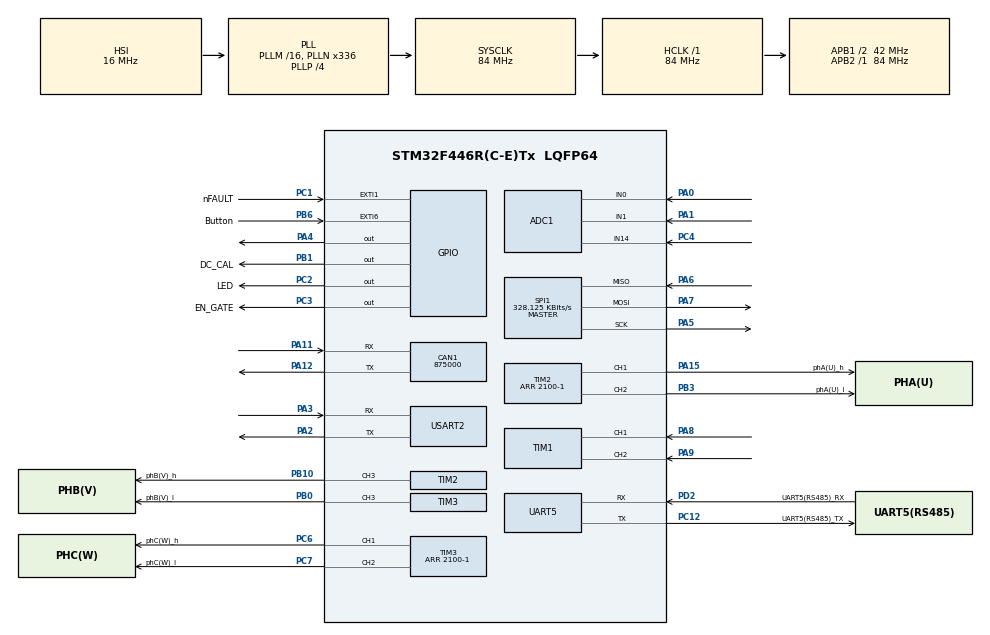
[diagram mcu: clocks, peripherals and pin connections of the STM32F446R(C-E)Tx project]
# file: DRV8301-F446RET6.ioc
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ADC1.Channel-0\#ChannelRegularConversion=ADC_CHANNEL_14
ADC1.Channel-2\#ChannelInjectedConversion=ADC_CHANNEL_0
ADC1.Channel-4\#ChannelInjectedConversion=ADC_CHANNEL_1
ADC1.ClockPrescaler=ADC_CLOCK_SYNC_PCLK_DIV4
ADC1.ContinuousConvMode=DISABLE
ADC1.ExternalTrigConv=ADC_SOFTWARE_START
ADC1.ExternalTrigInjecConv=ADC_EXTERNALTRIGINJECCONV_T2_TRGO
ADC1.InjNumberOfConversion=2
ADC1.InjectedConvMode=None
ADC1.InjectedOffset-2\#ChannelInjectedConversion=0
ADC1.InjectedOffset-4\#ChannelInjectedConversion=0
ADC1.InjectedRank-2\#ChannelInjectedConversion=1
ADC1.InjectedRank-4\#ChannelInjectedConversion=2
ADC1.NbrOfConversion=1
ADC1.NbrOfConversionFlag=1
ADC1.Rank-0\#ChannelRegularConversion=1
ADC1.SamplingTime-0\#ChannelRegularConversion=ADC_SAMPLETIME_3CYCLES
ADC1.SamplingTime-2\#ChannelInjectedConversion=ADC_SAMPLETIME_56CYCLES
ADC1.SamplingTime-4\#ChannelInjectedConversion=ADC_SAMPLETIME_56CYCLES
ADC1.ScanConvMode=ENABLE
ADC1.master=1
CAN1.BS1=CAN_BS1_1TQ
CAN1.BS2=CAN_BS2_1TQ
CAN1.CalculateBaudRate=875000
CAN1.CalculateTimeBit=1142
CAN1.CalculateTimeQuantum=380.95238095238096
Mcu.Family=STM32F4
Mcu.Name=STM32F446R(C-E)Tx
Mcu.Package=LQFP64
NVIC.ADC_IRQn=true\:0\:0\:false\:false\:true\:true\:true\:true
NVIC.EXTI1_IRQn=true\:0\:0\:false\:false\:true\:true\:true\:true
NVIC.EXTI9_5_IRQn=true\:0\:0\:false\:false\:true\:true\:true\:true
NVIC.PriorityGroup=NVIC_PRIORITYGROUP_4
NVIC.SPI1_IRQn=true\:0\:0\:false\:false\:true\:true\:true\:true
NVIC.TIM1_UP_TIM10_IRQn=true\:0\:0\:false\:false\:true\:true\:true\:true
NVIC.TIM3_IRQn=true\:0\:0\:false\:false\:true\:true\:true\:true
NVIC.TIM8_TRG_COM_TIM14_IRQn=true\:15\:0\:false\:false\:true\:false\:true\:true
NVIC.TimeBase=TIM8_TRG_COM_TIM14_IRQn
NVIC.TimeBaseIP=TIM14
NVIC.UART5_IRQn=true\:0\:0\:false\:false\:true\:true\:true\:true
NVIC.USART2_IRQn=true\:0\:0\:false\:false\:true\:true\:true\:true
PA0-WKUP.Signal=ADCx_IN0
PA1.Signal=ADCx_IN1
PA11.Mode=CAN_Activate
PA11.Signal=CAN1_RX
PA12.Mode=CAN_Activate
PA12.Signal=CAN1_TX
PA13.Mode=Serial_Wire
PA13.Signal=SYS_JTMS-SWDIO
PA14.Mode=Serial_Wire
PA14.Signal=SYS_JTCK-SWCLK
PA15.GPIO_Label=phA(U)_h
PA15.Signal=S_TIM2_CH1_ETR
PA2.Mode=Asynchronous
PA2.Signal=USART2_TX
PA3.Mode=Asynchronous
PA3.Signal=USART2_RX
PA4.GPIO_Label=SPI\uFF12\uFF3FNSS\uFF08CS\uFF09
PA4.GPIO_Speed=GPIO_SPEED_FREQ_VERY_HIGH
PA4.PinState=GPIO_PIN_SET
PA4.Signal=GPIO_Output
PA5.Mode=Full_Duplex_Master
PA5.Signal=SPI1_SCK
PA6.Mode=Full_Duplex_Master
PA6.Signal=SPI1_MISO
PA7.Mode=Full_Duplex_Master
PA7.Signal=SPI1_MOSI
PA8.Signal=S_TIM1_CH1
PA9.Signal=S_TIM1_CH2
PB0.GPIO_Label=phB(V)_l
PB0.Signal=S_TIM3_CH3
PB1.GPIO_Label=DC_CAL
PB1.PinState=GPIO_PIN_RESET
PB1.Signal=GPIO_Output
PB10.GPIO_Label=phB(V)_h
PB10.Signal=S_TIM2_CH3
PB3.GPIO_Label=phA(U)_l
PB3.Signal=S_TIM2_CH2
PB6.GPIO_Label=Button
PB6.GPIO_ModeDefaultEXTI=GPIO_MODE_IT_FALLING
PB6.Signal=GPXTI6
PC1.GPIO_Label=nFAULT
PC1.GPIO_ModeDefaultEXTI=GPIO_MODE_IT_FALLING
PC1.GPIO_PuPd=GPIO_PULLUP
PC1.Signal=GPXTI1
PC12.GPIO_Label=UART5(RS485)_TX
PC12.Mode=Asynchronous
PC12.Signal=UART5_TX
PC13.Mode=SYS_WakeUp1
PC13.Signal=SYS_WKUP1
PC14-OSC32_IN.Mode=LSE-External-Oscillator
PC14-OSC32_IN.Signal=RCC_OSC32_IN
PC15-OSC32_OUT.Mode=LSE-External-Oscillator
PC15-OSC32_OUT.Signal=RCC_OSC32_OUT
PC2.GPIO_Label=LED
PC2.Signal=GPIO_Output
PC3.GPIO_Label=EN_GATE
PC3.Signal=GPIO_Output
PC4.Signal=ADCx_IN14
PC6.GPIO_Label=phC(W)_h
PC6.Signal=S_TIM3_CH1
PC7.GPIO_Label=phC(W)_l
PC7.Signal=S_TIM3_CH2
PD2.GPIO_Label=UART5(RS485)_RX
PD2.Mode=Asynchronous
PD2.Signal=UART5_RX
PH0-OSC_IN.Mode=HSE-External-Oscillator
PH0-OSC_IN.Signal=RCC_OSC_IN
PH1-OSC_OUT.Mode=HSE-External-Oscillator
PH1-OSC_OUT.Signal=RCC_OSC_OUT
ProjectManager.HeapSize=0x200
ProjectManager.StackSize=0x400
ProjectManager.TargetToolchain=CMake
RCC.AHBFreq_Value=84000000
RCC.APB1CLKDivider=RCC_HCLK_DIV2
RCC.APB1Freq_Value=42000000
RCC.APB1TimFreq_Value=84000000
RCC.APB2Freq_Value=84000000
RCC.APB2TimFreq_Value=84000000
RCC.CortexFreq_Value=84000000
RCC.HCLKFreq_Value=84000000
RCC.PLLN=336
RCC.PLLP=RCC_PLLP_DIV4
RCC.SYSCLKFreq_VALUE=84000000
RCC.SYSCLKSource=RCC_SYSCLKSOURCE_PLLCLK
RCC.USBFreq_Value=168000000
RCC.VCOOutputFreq_Value=336000000
SH.ADCx_IN0.0=ADC1_IN0,IN0
SH.ADCx_IN1.0=ADC1_IN1,IN1
SH.ADCx_IN14.0=ADC1_IN14,IN14
SH.S_TIM1_CH1.0=TIM1_CH1,Encoder_Interface
SH.S_TIM1_CH2.0=TIM1_CH2,Encoder_Interface
SH.S_TIM2_CH1_ETR.0=TIM2_CH1,PWM Generation1 CH1
SH.S_TIM2_CH2.0=TIM2_CH2,PWM Generation2 CH2
SH.S_TIM2_CH3.0=TIM2_CH3,PWM Generation3 CH3
SH.S_TIM3_CH1.0=TIM3_CH1,PWM Generation1 CH1
SH.S_TIM3_CH2.0=TIM3_CH2,PWM Generation2 CH2
SH.S_TIM3_CH3.0=TIM3_CH3,PWM Generation3 CH3
SPI1.BaudRatePrescaler=SPI_BAUDRATEPRESCALER_256
SPI1.CalculateBaudRate=328.125 KBits/s
SPI1.DataSize=SPI_DATASIZE_16BIT
SPI1.Direction=SPI_DIRECTION_2LINES
SPI1.Mode=SPI_MODE_MASTER
SPI1.VirtualType=VM_MASTER
TIM1.EncoderMode=TIM_ENCODERMODE_TI12
TIM10.Period=1000-1
TIM10.Prescaler=8400-1
TIM2.AutoReloadPreload=TIM_AUTORELOAD_PRELOAD_ENABLE
TIM2.Channel-PWM\ Generation1\ CH1=TIM_CHANNEL_1
TIM2.Channel-PWM\ Generation2\ CH2=TIM_CHANNEL_2
TIM2.Channel-PWM\ Generation3\ CH3=TIM_CHANNEL_3
TIM2.Channel-PWM\ Generation4\ No\ Output=TIM_CHANNEL_4
TIM2.CounterMode=TIM_COUNTERMODE_CENTERALIGNED1
TIM2.OCMode_PWM-PWM\ Generation4\ No\ Output=TIM_OCMODE_PWM2
TIM2.Period=2100-1
TIM2.TIM_MasterOutputTrigger=TIM_TRGO_OC4REF
TIM3.AutoReloadPreload=TIM_AUTORELOAD_PRELOAD_ENABLE
TIM3.Channel-PWM\ Generation1\ CH1=TIM_CHANNEL_1
TIM3.Channel-PWM\ Generation2\ CH2=TIM_CHANNEL_2
TIM3.Channel-PWM\ Generation3\ CH3=TIM_CHANNEL_3
TIM3.CounterMode=TIM_COUNTERMODE_CENTERALIGNED1
TIM3.Period=2100-1
TIM3.TIM_MasterOutputTrigger=TIM_TRGO_RESET
TIM3.TIM_MasterSlaveMode=TIM_MASTERSLAVEMODE_DISABLE
UART5.VirtualMode=Asynchronous
USART2.VirtualMode=VM_ASYNC
VP_SYS_VS_tim14.Mode=TIM14
VP_TIM10_VS_ClockSourceINT.Mode=Enable_Timer
VP_TIM2_VS_ClockSourceINT.Mode=Internal
VP_TIM2_VS_no_output4.Mode=PWM Generation4 No Output
VP_TIM3_VS_ClockSourceINT.Mode=Internal
VP_TIM3_VS_ClockSourceITR.Mode=TriggerSource_ITR1
VP_TIM3_VS_ControllerModeReset.Mode=Reset Mode
board=custom

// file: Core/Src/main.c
/* USER CODE BEGIN Header */
/**
  ******************************************************************************
  * @file           : main.c
  * @brief          : Main program body
  ******************************************************************************
  * @attention
  *
  * Copyright (c) 2025 STMicroelectronics.
  * All rights reserved.
  *
  * This software is licensed under terms that can be found in the LICENSE file
  * in the root directory of this software component.
  * If no LICENSE file comes with this software, it is provided AS-IS.
  *
  ******************************************************************************
  */
/* USER CODE END Header */
#include "main.h"
#include "adc.h"
#include "can.h"
#include "spi.h"
#include "tim.h"
#include "usart.h"
#include "gpio.h"

/* USER CODE BEGIN Includes */
#include "main.hpp"

#include <string.h>
/* USER CODE END Includes */

void SystemClock_Config(void);

int main(void)
{

  /* MCU Configuration--------------------------------------------------------*/

  /* Reset of all peripherals, Initializes the Flash interface and the Systick. */
  HAL_Init();

  /* Configure the system clock */
  SystemClock_Config();

  /* Initialize all configured peripherals */
  MX_GPIO_Init();
  MX_ADC1_Init();
  MX_CAN1_Init();
  MX_SPI1_Init();
  MX_TIM1_Init();
  MX_TIM2_Init();
  MX_TIM3_Init();
  MX_UART5_Init();
  MX_USART2_UART_Init();
  MX_TIM10_Init();
  /* USER CODE BEGIN 2 */
  setup();
  /* USER CODE END 2 */

  /* Infinite loop */
  /* USER CODE BEGIN WHILE */
  while (1)
  {
    loop();
    /* USER CODE END WHILE */

  }
}

void SystemClock_Config(void)
{
  RCC_OscInitTypeDef RCC_OscInitStruct = {0};
  RCC_ClkInitTypeDef RCC_ClkInitStruct = {0};

  /** Configure the main internal regulator output voltage
  */
  __HAL_RCC_PWR_CLK_ENABLE();
  __HAL_PWR_VOLTAGESCALING_CONFIG(PWR_REGULATOR_VOLTAGE_SCALE3);

  /** Initializes the RCC Oscillators according to the specified parameters
  * in the RCC_OscInitTypeDef structure.
  */
  RCC_OscInitStruct.OscillatorType = RCC_OSCILLATORTYPE_HSI;
  RCC_OscInitStruct.HSIState = RCC_HSI_ON;
  RCC_OscInitStruct.HSICalibrationValue = RCC_HSICALIBRATION_DEFAULT;
  RCC_OscInitStruct.PLL.PLLState = RCC_PLL_ON;
  RCC_OscInitStruct.PLL.PLLSource = RCC_PLLSOURCE_HSI;
  RCC_OscInitStruct.PLL.PLLM = 16;
  RCC_OscInitStruct.PLL.PLLN = 336;
  RCC_OscInitStruct.PLL.PLLP = RCC_PLLP_DIV4;
  RCC_OscInitStruct.PLL.PLLQ = 2;
  RCC_OscInitStruct.PLL.PLLR = 2;
  if (HAL_RCC_OscConfig(&RCC_OscInitStruct) != HAL_OK)
  {
    Error_Handler();
  }

  /** Initializes the CPU, AHB and APB buses clocks
  */
  RCC_ClkInitStruct.ClockType = RCC_CLOCKTYPE_HCLK|RCC_CLOCKTYPE_SYSCLK
                              |RCC_CLOCKTYPE_PCLK1|RCC_CLOCKTYPE_PCLK2;
  RCC_ClkInitStruct.SYSCLKSource = RCC_SYSCLKSOURCE_PLLCLK;
  RCC_ClkInitStruct.AHBCLKDivider = RCC_SYSCLK_DIV1;
  RCC_ClkInitStruct.APB1CLKDivider = RCC_HCLK_DIV2;
  RCC_ClkInitStruct.APB2CLKDivider = RCC_HCLK_DIV1;

  if (HAL_RCC_ClockConfig(&RCC_ClkInitStruct, FLASH_LATENCY_2) != HAL_OK)
  {
    Error_Handler();
  }
}

void HAL_TIM_PeriodElapsedCallback(TIM_HandleTypeDef *htim)
{
  /* USER CODE BEGIN Callback 0 */
  // 割り込み直前処理
  /* USER CODE END Callback 0 */
  if (htim->Instance == TIM14) {
    HAL_IncTick();
  }
  /* USER CODE BEGIN Callback 1 */
  // 割り込み直後処理
  // C++ 側に処理を委譲
  HAL_User_TIM_PeriodElapsedCallback(htim); // main.cppの関数を呼び出し
  /* USER CODE END Callback 1 */
}

void Error_Handler(void)
{
  __disable_irq();
  while (1)
  {
  }
}
